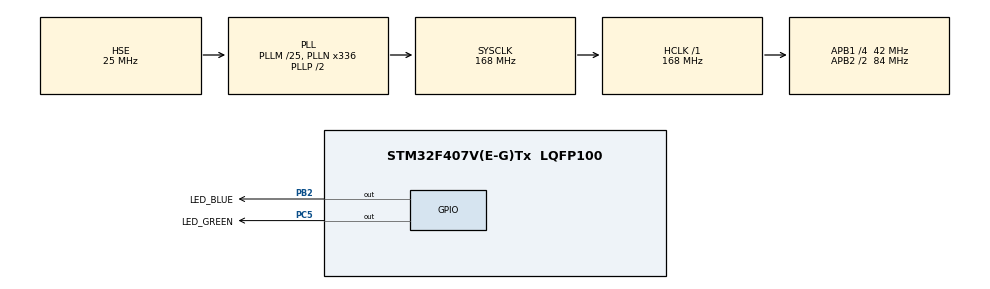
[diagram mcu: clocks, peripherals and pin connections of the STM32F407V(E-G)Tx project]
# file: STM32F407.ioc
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Mcu.Family=STM32F4
Mcu.Name=STM32F407V(E-G)Tx
Mcu.Package=LQFP100
NVIC.PriorityGroup=NVIC_PRIORITYGROUP_4
NVIC.TIM1_UP_TIM10_IRQn=true\:0\:0\:false\:false\:true\:true\:true\:true
PA13.Mode=Serial_Wire
PA13.Signal=SYS_JTMS-SWDIO
PA14.Mode=Serial_Wire
PA14.Signal=SYS_JTCK-SWCLK
PB2.GPIO_Label=LED_BLUE
PB2.Signal=GPIO_Output
PC5.GPIO_Label=LED_GREEN
PC5.Signal=GPIO_Output
PH0-OSC_IN.Mode=HSE-External-Oscillator
PH0-OSC_IN.Signal=RCC_OSC_IN
PH1-OSC_OUT.Mode=HSE-External-Oscillator
PH1-OSC_OUT.Signal=RCC_OSC_OUT
ProjectManager.HeapSize=0x200
ProjectManager.StackSize=0x1000
ProjectManager.TargetToolchain=MDK-ARM V5.32
RCC.48MHZClocksFreq_Value=84000000
RCC.AHBFreq_Value=168000000
RCC.APB1CLKDivider=RCC_HCLK_DIV4
RCC.APB1Freq_Value=42000000
RCC.APB1TimFreq_Value=84000000
RCC.APB2CLKDivider=RCC_HCLK_DIV2
RCC.APB2Freq_Value=84000000
RCC.APB2TimFreq_Value=168000000
RCC.CortexFreq_Value=168000000
RCC.HCLKFreq_Value=168000000
RCC.HSE_VALUE=25000000
RCC.HSI_VALUE=16000000
RCC.LSE_VALUE=32768
RCC.PLLM=25
RCC.PLLN=336
RCC.PLLSourceVirtual=RCC_PLLSOURCE_HSE
RCC.SYSCLKFreq_VALUE=168000000
RCC.SYSCLKSource=RCC_SYSCLKSOURCE_PLLCLK
RCC.VCOOutputFreq_Value=336000000
TIM1.AutoReloadPreload=TIM_AUTORELOAD_PRELOAD_ENABLE
TIM1.Period=1000-1
TIM1.Prescaler=168-1
TIM1.RepetitionCounter=0
VP_TIM1_VS_ClockSourceINT.Mode=Internal
board=custom

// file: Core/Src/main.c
/* USER CODE BEGIN Header */
/**==================================================================================================================
 ** 【代码编写】  魔女开发板团队
 ** 【淘    宝】  魔女开发板       https://demoboard.taobao.com
 **==================================================================================================================
 ** 【实验名称】  高级定时器 TIM1 定时测试
 **
 ** 【适用平台】  STM32F407 + keil5 + HAL库
 **
 ** 【实验目标】  通过TIM1配置定时，每隔1秒反转LED;
 **
 ** 【引脚接线】  为了方便观察实验效果，可以使用以下两种方法;
 **               1-使用板上的LED_BLUE(PB2) 配合测试。
 **               2_如果有示波器，示波器通道接上PB2,  共地。
 **
 ** 【 CubeMX 】  打开Timers，选择TIM1;
 **               Clock Source(时钟源): Internal Clock    内部时钟
 **               Prescaler(PSC)      ：168-1             分频值      基本定时器的时钟源是84MHz, 84分频后脉冲频率为1MHz, 即每1us产生一个计数信号。
 **               Counter Period(ARR) : 1000-1            周期值      多少个计数信号组成一个周期
 **               auto-reload preload : Enable            预装载      使能后，更改ARR值不会打断当前波形
 **               NVIC Settings(中断) : update interrupt  打勾        周期更新中断
 **
 ** 【初 始 化】  1-TIM1的初始化代码，CubeMX会根据配置自动生成。
 **               2-只需在main函数中，调用函数开启TIM1、打开中断.
 **
 ** 【回调函数】  1-使用CubeMX生成工程，其生成的代码会编写好中断服务函数、清理中断标志、调用中断回调函数。我们只需重写回调函数，并在其中执行自定义操作。
 **               2-高级定时器，有多个中断，我们在CubeMX中使用的是update interrupt(周期更新中断), 当CNT计数达到1周期值时触发，硬件自动调用中断服务函数，继而调用其中断回调函数：HAL_TIM_PeriodElapsedCallback();
 **               3-中断回调函数，本示例写在了main.c的底部。你可以写在工程的任意一个c文件中。
 **
 ** 【TIM 重点】  1_时钟频率：STM32F407默认系统频率168MHz; TIM1、8、9、10、11的时钟频率是APB2*2=84MHz*2=168MHz, 而TIM1、3、4、5、6、7、12、13、14的时钟频率是APB1*2=42MHz*2=84MHz;
 **               2_基本定时器、通用定时器、高级定时器资源是有明显区别的，已整理有《TIM资源表》存放在示例文件夹中，仅供参考;
 **               3_PSC，预分频值;    作用：控制计数器每一脉冲的时长; 解释：把时钟源分频后提供给计数器使用，即多少个时钟源脉冲，才产生一次计数器脉冲;
 **               4_ARR，自动重载值;  作用：控制周期; 解释：多少个计数器脉冲，组成一完整波形周期;
 **               5_CNT，计数器;      作用：每一脉冲，硬件自动操作递增、递减;
 **               6_CCR，捕获/比较值; 作用：输出模式用于与CNT值作大小比较而输出有效电平; 输入模式用于记录上一捕获时的计数器值; 注意，基本定时器TIM6和7没有CCR寄存器。
 **               7_寄存器位宽:所有TIM的PSC寄存器，都是16位的，取值范围：1~65535; 注意：ARR、CNT、CCR三个寄存器，除了TIM1和5是32位，其它TIM的都是16位;
 **               8_输出极性，理解为有效电平。在TIM_OCPolarity里设置，可以设置为高、低电平; 如，当PWM1模式下，当CNT<CCR时输出有效电平，这个有效电平，就是你设置的“输出极性”; 注意：基本定时器TIM6和7没有这个概念.
 **               9_中断回调函数：如果使用CubeMX生成工程，其生成的代码会编写好中断服务函数、清理中断标志、调用中断回调函数。我们只需重写回调函数，并在其中执行自定义操作。
 **
 ** 【更新记录】  2024-03-06  新建HAL库工程
 **
 ** 【备注说明】  版权归魔女科技所有，请勿商用，谢谢！
 **               https://demoboard.taobao.com
 **
==================================================================================================================**/
/* USER CODE END Header */
#include "main.h"
#include "tim.h"
#include "gpio.h"

/* USER CODE BEGIN Includes */
/* 用户代码，必须写在配对的BEGIN与END之间，否则CubeMX重新生成后，会被删除掉 */

#include "bsp_UART.h"            // 串口通信底层驱动文件; 已重写好初始化、收发，调用函数即可使用串口

/* USER CODE END Includes */

void SystemClock_Config(void);

int main(void)
{
    /* USER CODE BEGIN 1 */

    /* 说明：
     * 1. 不要删除CubeMX生成的注释行（形如 USER CODE BEGIN/END），这些注释用于代码重新生成时的定位
     * 2. 所有用户自定义代码必须写在对应的BEGIN与END注释行之间，否则重新生成时会被覆盖
     * 3. 主要初始化函数说明：
     *    - HAL_Init()            初始化HAL库，配置中断优先级、系统时基等
     *    - SystemClock_Config()  配置系统时钟
     *    - MX_GPIO_Init()        初始化GPIO引脚（仅包含推挽输出、中断触发等配置）
     *    - 外设功能引脚（如UART、SPI等）的初始化在各自的功能文件中
     */

    /* USER CODE END 1 */

    /* MCU Configuration--------------------------------------------------------*/

    /* Reset of all peripherals, Initializes the Flash interface and the Systick. */
    HAL_Init();

    /* Configure the system clock */
    SystemClock_Config();

    /* Initialize all configured peripherals */
    MX_GPIO_Init();
    MX_TIM1_Init();
    /* USER CODE BEGIN 2 */
    /* 用户代码，必须写在配对的BEGIN与END之间 */

    HAL_GPIO_WritePin(GPIOC, GPIO_PIN_5, GPIO_PIN_SET);                    // 引脚置高电平，绿亮灭

    UART1_Init(115200);                                                    // 初始化 串口1; 已写好底层，调用h中的函数即可使用; 引脚(PA9 +PA10)、波特率-None-8-1; 如果使用CubeMX配置，请使用前述引脚，但，不要在MX上进行中断及DMA配置，否则冲突

    HAL_TIM_Base_Start_IT(&htim1);                                         // 启动TIM1，并使能中断

    /* USER CODE END 2 */

    /* Infinite loop */
    while (1)
    {

        /* USER CODE BEGIN 3 */
        /* 用户代码，必须写在配对的BEGIN与END之间 */

    }

    /* USER CODE END 3 */
}

void SystemClock_Config(void)
{
    RCC_OscInitTypeDef RCC_OscInitStruct = {0};
    RCC_ClkInitTypeDef RCC_ClkInitStruct = {0};

    /** Configure the main internal regulator output voltage
    */
    __HAL_RCC_PWR_CLK_ENABLE();
    __HAL_PWR_VOLTAGESCALING_CONFIG(PWR_REGULATOR_VOLTAGE_SCALE1);

    /** Initializes the RCC Oscillators according to the specified parameters
    * in the RCC_OscInitTypeDef structure.
    */
    RCC_OscInitStruct.OscillatorType = RCC_OSCILLATORTYPE_HSE;
    RCC_OscInitStruct.HSEState = RCC_HSE_ON;
    RCC_OscInitStruct.PLL.PLLState = RCC_PLL_ON;
    RCC_OscInitStruct.PLL.PLLSource = RCC_PLLSOURCE_HSE;
    RCC_OscInitStruct.PLL.PLLM = 25;
    RCC_OscInitStruct.PLL.PLLN = 336;
    RCC_OscInitStruct.PLL.PLLP = RCC_PLLP_DIV2;
    RCC_OscInitStruct.PLL.PLLQ = 4;
    if (HAL_RCC_OscConfig(&RCC_OscInitStruct) != HAL_OK)
    {
        Error_Handler();
    }

    /** Initializes the CPU, AHB and APB buses clocks
    */
    RCC_ClkInitStruct.ClockType = RCC_CLOCKTYPE_HCLK | RCC_CLOCKTYPE_SYSCLK
                                  | RCC_CLOCKTYPE_PCLK1 | RCC_CLOCKTYPE_PCLK2;
    RCC_ClkInitStruct.SYSCLKSource = RCC_SYSCLKSOURCE_PLLCLK;
    RCC_ClkInitStruct.AHBCLKDivider = RCC_SYSCLK_DIV1;
    RCC_ClkInitStruct.APB1CLKDivider = RCC_HCLK_DIV4;
    RCC_ClkInitStruct.APB2CLKDivider = RCC_HCLK_DIV2;

    if (HAL_RCC_ClockConfig(&RCC_ClkInitStruct, FLASH_LATENCY_5) != HAL_OK)
    {
        Error_Handler();
    }
}

/* USER CODE BEGIN 4 */
/* 所有用户代码，必须写在配对的BEGIN与END之间 */

/******************************************************************************
 * 函  数： HAL_TIM_PeriodElapsedCallback
 * 功  能： 周期更新回调函数
 * 备  注： 本函数是TIM的CNT溢出中断回调函数。
 *          当TIM的计数器CNT，完成1周期计数时触发(向上计数：CNT==ARR，向下计数：CNT==0);
 *          上述中断触发后，硬件自动调用相关中断服务函数，继而调用本函数。
 *          所有TIM的周期更新中断，都是调用本函数，因此需要在函数内判断是哪一个TIM触发的中断;
 * 参  数： TIM_HandleTypeDef   *htim
 * 返回值： 无
******************************************************************************/
void HAL_TIM_PeriodElapsedCallback(TIM_HandleTypeDef *htim)
{
    if (htim->Instance == TIM1)                             // 判断是哪个TIM产生的中断
    {
        static uint16_t cnt = 0;                            // 中断次数
        if (cnt++ >= 1000)                                  // 每中断1000次执行，即1s执行1次
        {
            HAL_GPIO_TogglePin(GPIOB, GPIO_PIN_2);          // 反转LED引脚
            cnt = 0;                                        // 计数清0
        }
    }

}

/* USER CODE END 4 */

void Error_Handler(void)
{
    __disable_irq();
    while (1)
    {
    }
}
